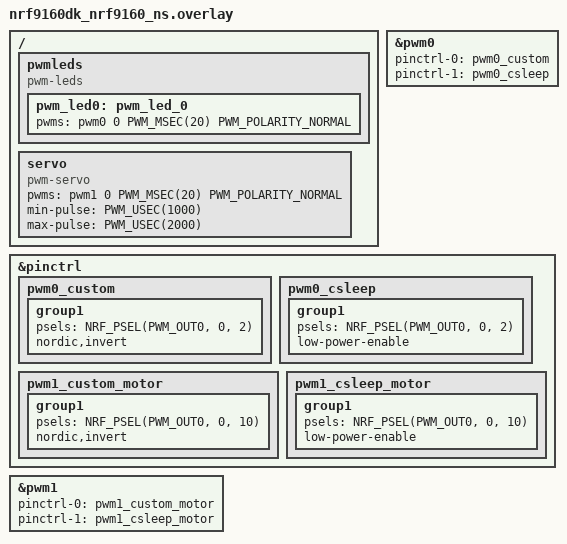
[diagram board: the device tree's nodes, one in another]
/* STEP 1.2 -  Add a pwm_led instance and change the polarity */
/{
    pwmleds {
        compatible = "pwm-leds";
        pwm_led0: pwm_led_0 {
            pwms = <&pwm0 0 PWM_MSEC(20) PWM_POLARITY_NORMAL>;
        };
    };
};

/* STEP 1.3 - Add your own custom pwm0 instance */
&pwm0 {
    status = "okay";
    pinctrl-0 = <&pwm0_custom>;
    pinctrl-1 = <&pwm0_csleep>;
    pinctrl-names = "default", "sleep";
};

/* STEP 1.4 - Configure which pins your custom pwm0 instance should use */
/* STEP 4.1 - Configure pwm0 to drive the GPIO pin for LED 1 */
&pinctrl {
    pwm0_custom: pwm0_custom {
        group1 {
            psels = <NRF_PSEL(PWM_OUT0, 0, 2)>;
            nordic,invert;
        };
    };

    pwm0_csleep: pwm0_csleep {
        group1 {
            psels = <NRF_PSEL(PWM_OUT0, 0, 2)>;
            low-power-enable;
        };
    };
};


/* STEP 5.2 - Add the servo device */
/ {
    servo: servo {
        compatible = "pwm-servo";
        pwms = <&pwm1 0 PWM_MSEC(20) PWM_POLARITY_NORMAL>;
        min-pulse = <PWM_USEC(1000)>;
        max-pulse = <PWM_USEC(2000)>;
    };
};

/* STEP 5.3 - Configure which pins pwm1 should use */
&pwm1 {
    status = "okay";
    pinctrl-0 = <&pwm1_custom_motor>;
    pinctrl-1 = <&pwm1_csleep_motor>;
    pinctrl-names = "default", "sleep";
};

&pinctrl {
    pwm1_custom_motor: pwm1_custom_motor {
        group1 {
            psels = <NRF_PSEL(PWM_OUT0, 0, 10)>;
            nordic,invert;
        };
    };

    pwm1_csleep_motor: pwm1_csleep_motor {
        group1 {
            psels = <NRF_PSEL(PWM_OUT0, 0, 10)>;
            low-power-enable;
        };
    };
};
